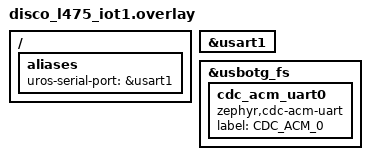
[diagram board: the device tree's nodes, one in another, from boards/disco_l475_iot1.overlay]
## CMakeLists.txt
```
# SPDX-License-Identifier: Apache-2.0

cmake_minimum_required(VERSION 3.13.1)

list(APPEND ZEPHYR_EXTRA_MODULES ${CMAKE_CURRENT_SOURCE_DIR}/modules/libmicroros)

find_package(Zephyr REQUIRED HINTS $ENV{ZEPHYR_BASE})
project(microros_sample_app)

target_sources(app PRIVATE src/main.c)
```

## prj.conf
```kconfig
CONFIG_GPIO=y
CONFIG_MICROROS=y
CONFIG_CPP=y

CONFIG_MAIN_STACK_SIZE=25000
CONFIG_MAIN_THREAD_PRIORITY=3

CONFIG_NEWLIB_LIBC=y
CONFIG_NEWLIB_LIBC_NANO=n
CONFIG_PTHREAD_IPC=n

CONFIG_POSIX_API=y
CONFIG_POSIX_CLOCK=y

CONFIG_STDOUT_CONSOLE=y
CONFIG_LOG=y
CONFIG_SERIAL=y
CONFIG_UART_INTERRUPT_DRIVEN=y
CONFIG_UART_LINE_CTRL=y
```

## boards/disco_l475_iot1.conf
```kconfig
CONFIG_USB_DEVICE_STACK=y
CONFIG_USB_DEVICE_PRODUCT="Zephyr micro-ROS"
CONFIG_LOG=y
CONFIG_USB_CDC_ACM=y
CONFIG_USB_DRIVER_LOG_LEVEL_ERR=y
CONFIG_USB_DEVICE_LOG_LEVEL_ERR=y
CONFIG_USB_CDC_ACM_RINGBUF_SIZE=2048
CONFIG_SERIAL=y
CONFIG_UART_INTERRUPT_DRIVEN=y
CONFIG_UART_LINE_CTRL=y
CONFIG_RING_BUFFER=y
CONFIG_GPIO=y
```

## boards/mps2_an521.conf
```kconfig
CONFIG_MICROROS_TRANSPORT_UDP=y
CONFIG_MICROROS_TRANSPORT_SERIAL=n
CONFIG_MICROROS_TRANSPORT_SERIAL_USB=n

# Generic networking options
CONFIG_NETWORKING=y
CONFIG_NET_UDP=y
CONFIG_NET_TCP=y
CONFIG_NET_IPV4=y
CONFIG_NET_SOCKETS=y
CONFIG_NET_SOCKETS_POSIX_NAMES=y
CONFIG_NET_SOCKETS_POLL_MAX=4
CONFIG_NET_CONNECTION_MANAGER=y

# Kernel options
CONFIG_ENTROPY_GENERATOR=y
CONFIG_TEST_RANDOM_GENERATOR=y
CONFIG_INIT_STACKS=y

# Logging
CONFIG_NET_LOG=y
CONFIG_LOG=y
CONFIG_NET_STATISTICS=y
CONFIG_PRINTK=y

# Network buffers
CONFIG_NET_PKT_RX_COUNT=16
CONFIG_NET_PKT_TX_COUNT=16
CONFIG_NET_BUF_RX_COUNT=80
CONFIG_NET_BUF_TX_COUNT=80
CONFIG_NET_CONTEXT_NET_PKT_POOL=y

# IP address options
CONFIG_NET_MAX_CONTEXTS=10

# Network shell
CONFIG_NET_SHELL=y
```

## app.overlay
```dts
/*Added these lines for compability with Zephyr v2.7*/
zephyr_udc0: &usbotg_fs {
	pinctrl-0 = <&usb_otg_fs_dm_pa11 &usb_otg_fs_dp_pa12
		     &usb_otg_fs_id_pa10>;
	pinctrl-names = "default";
	status = "okay";
};
/* End of compability part */


&zephyr_udc0 {
	cdc_acm_uart0: cdc_acm_uart0 {
		compatible = "zephyr,cdc-acm-uart";   
                label = "CDC_ACM_0";
        };
};
```

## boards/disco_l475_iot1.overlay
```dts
/ {
    aliases {
        uros-serial-port = &usart1;
    };
};

&usart1 {
    status = "okay";
};

zephyr_udc0: &usbotg_fs {
    status = "okay";
};

&zephyr_udc0 {
    cdc_acm_uart0: cdc_acm_uart0 {
            compatible = "zephyr,cdc-acm-uart";
            label = "CDC_ACM_0";
    };
};
```

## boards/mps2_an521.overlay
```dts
/ {
    aliases {
        uros-serial-port = &uart1;
    };

    chosen {
		zephyr,uart_pipe = &uart0;
	};

};

&uart1 {
    status = "okay";
};
```

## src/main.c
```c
#include <version.h>

#if ZEPHYR_VERSION_CODE >= ZEPHYR_VERSION(3,1,0)
#include <zephyr/kernel.h>
#include <zephyr/device.h>
#include <zephyr/devicetree.h>
#include <zephyr/drivers/gpio.h>
#include <zephyr/posix/time.h>
#else
#include <zephyr.h>
#include <device.h>
#include <devicetree.h>
#include <drivers/gpio.h>
#include <posix/time.h>
#endif

#include <rcl/rcl.h>
#include <rcl/error_handling.h>
#include <std_msgs/msg/int32.h>

#include <rclc/rclc.h>
#include <rclc/executor.h>

#include <rmw_microros/rmw_microros.h>
#include <microros_transports.h>

#define RCCHECK(fn) { rcl_ret_t temp_rc = fn; if((temp_rc != RCL_RET_OK)){printf("Failed status on line %d: %d. Aborting.\n",__LINE__,(int)temp_rc);for(;;){};}}
#define RCSOFTCHECK(fn) { rcl_ret_t temp_rc = fn; if((temp_rc != RCL_RET_OK)){printf("Failed status on line %d: %d. Continuing.\n",__LINE__,(int)temp_rc);}}

rcl_publisher_t publisher;
std_msgs__msg__Int32 msg;

void timer_callback(rcl_timer_t * timer, int64_t last_call_time)
{
	RCLC_UNUSED(last_call_time);
	if (timer != NULL) {
		RCSOFTCHECK(rcl_publish(&publisher, &msg, NULL));
		msg.data++;
	}
}

int main(void)
{
	rmw_uros_set_custom_transport(
		MICRO_ROS_FRAMING_REQUIRED,
		(void *) &default_params,
		zephyr_transport_open,
		zephyr_transport_close,
		zephyr_transport_write,
		zephyr_transport_read
	);

	rcl_allocator_t allocator = rcl_get_default_allocator();
	rclc_support_t support;

	// create init_options
	RCCHECK(rclc_support_init(&support, 0, NULL, &allocator));

	// create node
	rcl_node_t node;
	RCCHECK(rclc_node_init_default(&node, "zephyr_int32_publisher", "", &support));

	// create publisher
	RCCHECK(rclc_publisher_init_default(
		&publisher,
		&node,
		ROSIDL_GET_MSG_TYPE_SUPPORT(std_msgs, msg, Int32),
		"zephyr_int32_publisher"));

	// create timer,
	rcl_timer_t timer;
	const unsigned int timer_timeout = 1000;
	RCCHECK(rclc_timer_init_default(
		&timer,
		&support,
		RCL_MS_TO_NS(timer_timeout),
		timer_callback));

	// create executor
	rclc_executor_t executor;
	RCCHECK(rclc_executor_init(&executor, &support.context, 1, &allocator));
	RCCHECK(rclc_executor_add_timer(&executor, &timer));

	msg.data = 0;

	while(1){
		rclc_executor_spin_some(&executor, 100);
		usleep(100000);
	}

	// free resources
	RCCHECK(rcl_publisher_fini(&publisher, &node))
	RCCHECK(rcl_node_fini(&node))
  return 0;    
}
```
